# nrf7120_enga_application register map
Vendor: Nordic Semiconductor; Series: nrf71; File version: 1
CPU: CM33 r0p4, little endian, MPU, FPU, 3 interrupt priority bits, 270 interrupts, 4 SAU regions
Registers are 32-bit, read-write, reset 0x0 unless marked. A register's access mark holds for its fields unless they carry their own. Offsets are from the block's base; [hi:lo] are bit positions; lines under a group give offsets from that group; {n}, {i} and the like mark numbered series; 'fields as' and 'values as' point back to an identical list.

## GLOBAL_COEXC_NS — Coexistence controller 0
Base 0x400F1000
Same registers: GLOBAL_COEXC_S 0x500F1000
{0x400+8i} CCMALLOW[{i}] (i=0..7) group — Unspecified
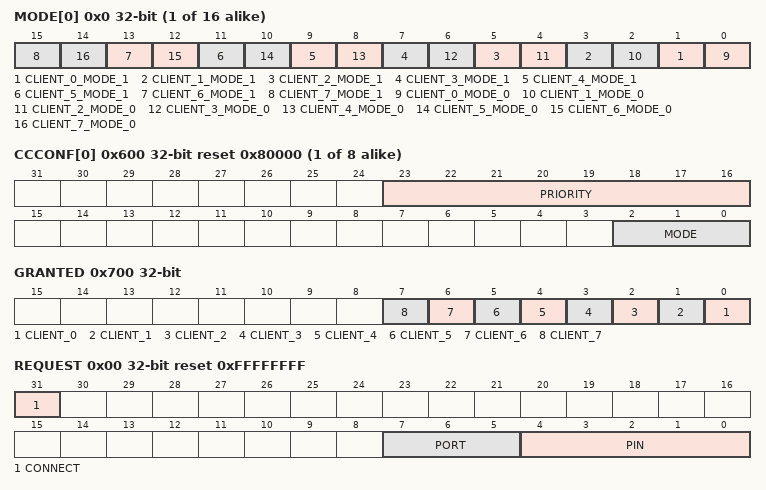
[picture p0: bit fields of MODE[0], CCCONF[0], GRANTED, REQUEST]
  {0x0+4j} MODE[{j}] (j=0..1) — Description collection: Coexistence client mode allow configuration for mode [o] in client [n]
    [all] fields
      0=NotAllowed (Coexistence not allowed); 1=Allow (Coexistence allowed)
    [2n+1] CLIENT_{n}_MODE_1 (n=0..7) — Coexistence allowed configuration for mode [1] in client [{n}]
    [2n] CLIENT_{n}_MODE_0 (n=0..7) — Coexistence allowed configuration for mode [0] in client [{n}]
{0x600+4i} CCCONF[{i}] (i=0..7) reset 0x80000 — Description collection: Configuration of coexistence client [n]
  [23:16] PRIORITY — Priority of the coexistence client [n]
  [2:0] MODE — Coexistence mode of the client [n]
{0x640+4i} TURNAROUND[{i}] (i=0..7) reset 0x280 — Description collection: Turnaround time for the coexistence client [n]
  [11:0] CLOCKCYCLES — Number of clock cycles
0x700 GRANTED ro — Granted status of the shared resource
  [n] CLIENT_{n} (n=0..7) — Granted status of coexistence clients
    0=NotGranted (Shared resource is not granted for coexistence client [{n}]); 1=Granted (Shared resource is granted for coexistence client [{n}])
0x704 PSEL group — Unspecified
  0x00 REQUEST reset 0xFFFFFFFF — Pin select for extRequest signal
    [31] CONNECT — Connection
      1=Disconnected; 0=Connected
    [7:5] PORT — Port number
    [4:0] PIN — Pin number
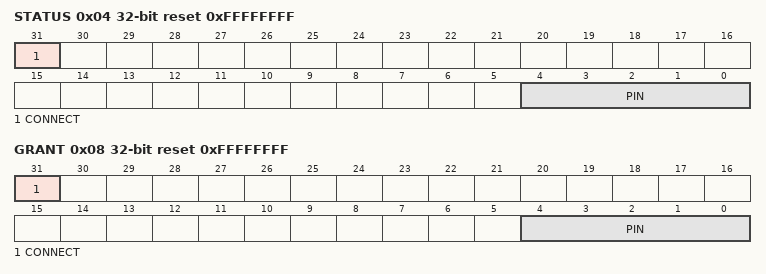
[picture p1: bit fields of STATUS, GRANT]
  0x04 STATUS reset 0xFFFFFFFF — Pin select for extStatus signal
    [31] CONNECT — Connection
      1=Disconnected; 0=Connected
    [4:0] PIN — Pin number
  0x08 GRANT reset 0xFFFFFFFF — Pin select for extGrant signal
    fields as PSEL.STATUS

## GLOBAL_POWER_NS — Power control 0
Base 0x4010E000; alternate view of GLOBAL_CLOCK_NS
Same registers: GLOBAL_POWER_S 0x5010E000 (alternate view of GLOBAL_CLOCK_S)
0x30 TASKS_CONSTLAT wo — Enable Constant Latency mode
  [0] TASKS_CONSTLAT
    1=Trigger task
0x34 TASKS_LOWPWR wo — Enable Low-power mode (variable latency)
  [0] TASKS_LOWPWR
    1=Trigger task
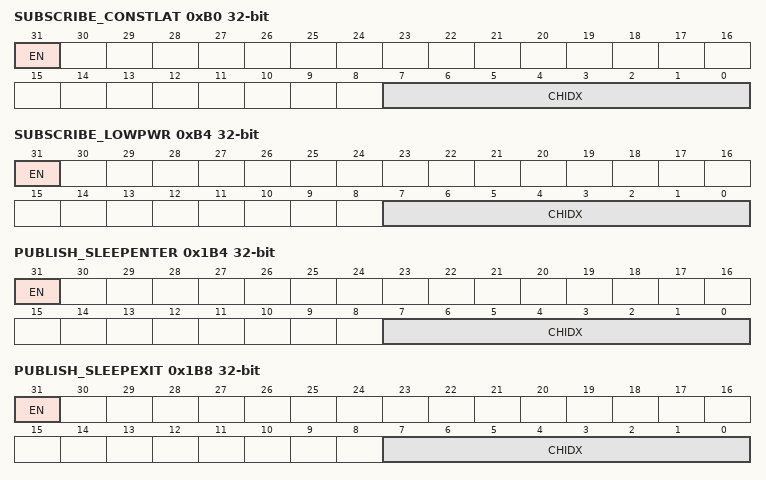
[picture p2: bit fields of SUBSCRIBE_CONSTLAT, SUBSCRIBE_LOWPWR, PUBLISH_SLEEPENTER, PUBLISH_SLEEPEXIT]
0xB0 SUBSCRIBE_CONSTLAT — Subscribe configuration for task CONSTLAT
  [31] EN
    0=Disabled (Disable subscription); 1=Enabled (Enable subscription)
  [7:0] CHIDX — DPPI channel that task CONSTLAT will subscribe to
0xB4 SUBSCRIBE_LOWPWR — Subscribe configuration for task LOWPWR
  [31] EN
    values as SUBSCRIBE_CONSTLAT.EN
  [7:0] CHIDX — DPPI channel that task LOWPWR will subscribe to
0x130 EVENTS_POFWARN — Power failure warning
  [0] EVENTS_POFWARN
    0=NotGenerated (Event not generated); 1=Generated (Event generated)
0x134 EVENTS_SLEEPENTER — CPU entered WFI/WFE sleep
  [0] EVENTS_SLEEPENTER
    values as EVENTS_POFWARN.EVENTS_POFWARN
0x138 EVENTS_SLEEPEXIT — CPU exited WFI/WFE sleep
  [0] EVENTS_SLEEPEXIT
    values as EVENTS_POFWARN.EVENTS_POFWARN
0x1B4 PUBLISH_SLEEPENTER — Publish configuration for event SLEEPENTER
  [31] EN
    0=Disabled (Disable publishing); 1=Enabled (Enable publishing)
  [7:0] CHIDX — DPPI channel that event SLEEPENTER will publish to
0x1B8 PUBLISH_SLEEPEXIT — Publish configuration for event SLEEPEXIT
  [31] EN
    values as PUBLISH_SLEEPENTER.EN
  [7:0] CHIDX — DPPI channel that event SLEEPEXIT will publish to
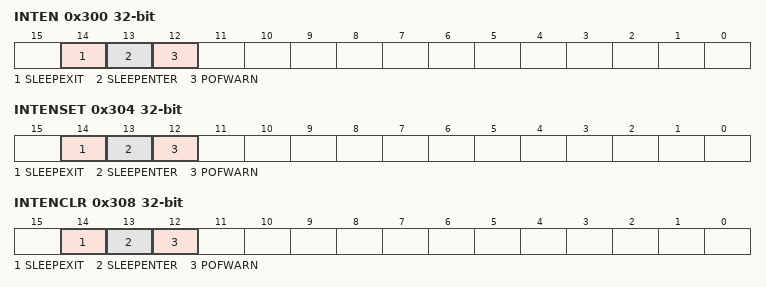
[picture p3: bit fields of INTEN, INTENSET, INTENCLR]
0x300 INTEN — Enable or disable interrupt
  [all] fields
    0=Disabled; 1=Enabled
  [14] SLEEPEXIT — Enable or disable interrupt for event SLEEPEXIT
  [13] SLEEPENTER — Enable or disable interrupt for event SLEEPENTER
  [12] POFWARN — Enable or disable interrupt for event POFWARN
0x304 INTENSET — Enable interrupt
  [all] fields
    on read: 0=Disabled (Read: Disabled); 1=Enabled (Read: Enabled) | on write: 1=Set (Enable)
  [14] SLEEPEXIT — Write '1' to enable interrupt for event SLEEPEXIT
  [13] SLEEPENTER — Write '1' to enable interrupt for event SLEEPENTER
  [12] POFWARN — Write '1' to enable interrupt for event POFWARN
0x308 INTENCLR — Disable interrupt
  [all] fields
    on read: 0=Disabled (Read: Disabled); 1=Enabled (Read: Enabled) | on write: 1=Clear (Disable)
  [14] SLEEPEXIT — Write '1' to disable interrupt for event SLEEPEXIT
  [13] SLEEPENTER — Write '1' to disable interrupt for event SLEEPENTER
  [12] POFWARN — Write '1' to disable interrupt for event POFWARN
{0x500+4i} GPREGRET[{i}] (i=0..1) — Description collection: General purpose retention register
  [7:0] GPREGRET — General purpose retention register
0x520 CONSTLATSTAT ro — Status of constant latency
  [0] STATUS
    0=Disable (Constant latency disabled); 1=Enable (Constant latency enabled)
